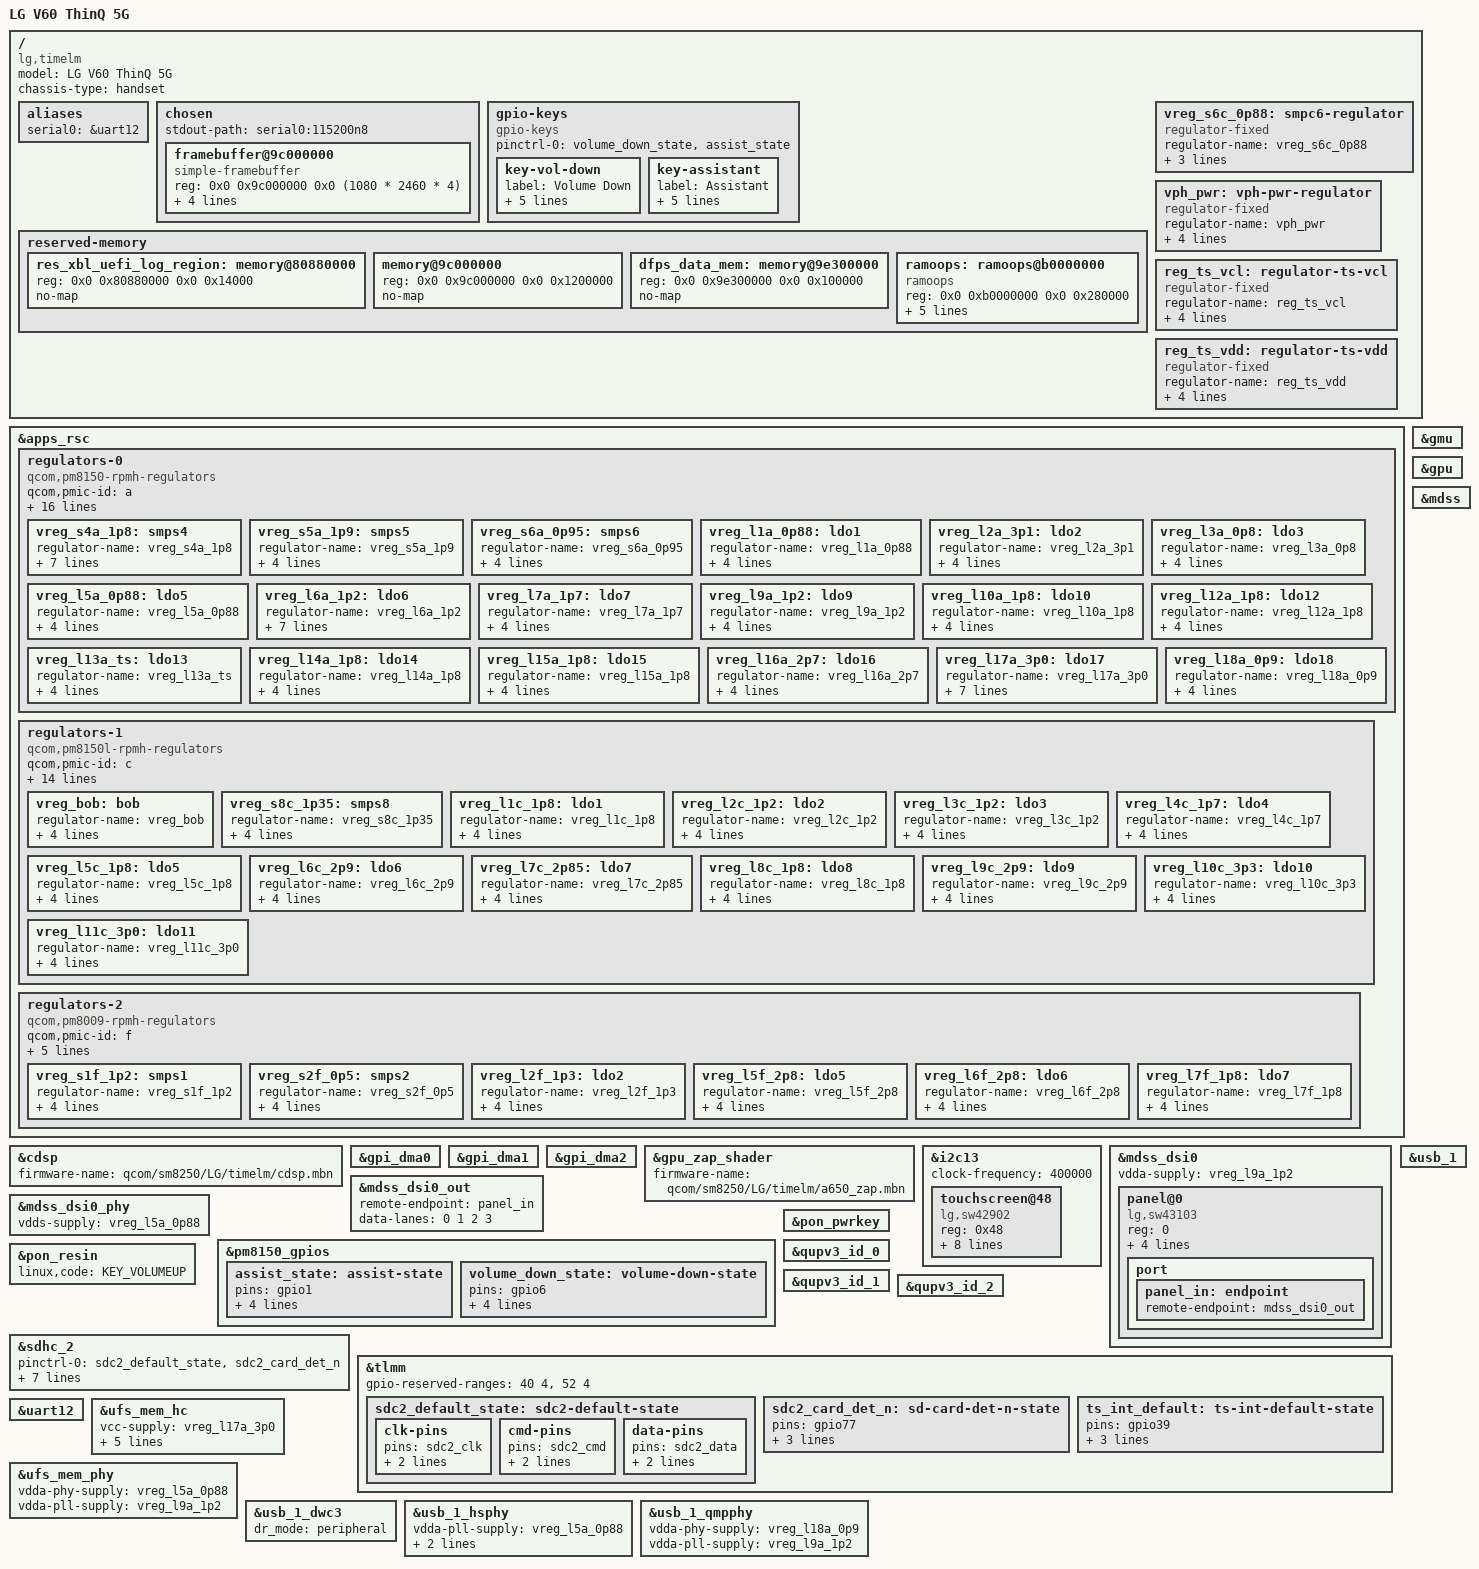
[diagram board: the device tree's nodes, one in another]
// SPDX-License-Identifier: BSD-3-Clause
/*
 * Copyright (c) 2026 Abdur Rofik <rofikcoga@gmail.com>
 * Device Tree for LG V60 ThinQ 5G (timelm / LM-V600)
 */

/dts-v1/;

#include <dt-bindings/gpio/gpio.h>
#include <dt-bindings/input/input.h>
#include <dt-bindings/regulator/qcom,rpmh-regulator.h>
#include "sm8250.dtsi"
#include "pm8150.dtsi"
#include "pm8150b.dtsi"
#include "pm8150l.dtsi"

/ {
	model = "LG V60 ThinQ 5G";
	compatible = "lg,timelm", "qcom,sm8250";
	chassis-type = "handset";

	aliases {
		serial0 = &uart12;
	};

	chosen {
		stdout-path = "serial0:115200n8";
		#address-cells = <2>;
		#size-cells = <2>;
		ranges;

		framebuffer@9c000000 {
			compatible = "simple-framebuffer";
			reg = <0x0 0x9c000000 0x0 (1080 * 2460 * 4)>;
			width = <1080>;
			height = <2460>;
			stride = <(1080 * 4)>;
			format = "a8r8g8b8";
		};
	};

	gpio-keys {
		compatible = "gpio-keys";

		pinctrl-names = "default";
		pinctrl-0 = <&volume_down_state>, <&assist_state>;

		key-vol-down {
			label = "Volume Down";
			gpios = <&pm8150_gpios 6 GPIO_ACTIVE_LOW>;
			linux,code = <KEY_VOLUMEDOWN>;
			debounce-interval = <15>;
			linux,can-disable;
			wakeup-source;
		};

		key-assistant {
			label = "Assistant";
			gpios = <&pm8150_gpios 1 GPIO_ACTIVE_LOW>;
			linux,code = <KEY_ASSISTANT>;
			debounce-interval = <15>;
			linux,can-disable;
			wakeup-source;
		};
	};

	reserved-memory {
		res_xbl_uefi_log_region: memory@80880000 {
			reg = <0x0 0x80880000 0x0 0x14000>;
			no-map;
		};

		memory@9c000000 {
			reg = <0x0 0x9c000000 0x0 0x1200000>;
			no-map;
		};

		dfps_data_mem: memory@9e300000 {
			reg = <0x0 0x9e300000 0x0 0x100000>;
			no-map;
		};

		ramoops: ramoops@b0000000 {
			compatible = "ramoops";
			reg = <0x0 0xb0000000 0x0 0x280000>;
			record-size = <0x40000>;
			console-size = <0x40000>;
			ftrace-size = <0x40000>;
			pmsg-size = <0x100000>;
			no-map;
		};
	};

	vreg_s6c_0p88: smpc6-regulator {
		compatible = "regulator-fixed";
		regulator-name = "vreg_s6c_0p88";
		regulator-min-microvolt = <880000>;
		regulator-max-microvolt = <880000>;
		regulator-always-on;
	};

	vph_pwr: vph-pwr-regulator {
		compatible = "regulator-fixed";
		regulator-name = "vph_pwr";
		regulator-min-microvolt = <3700000>;
		regulator-max-microvolt = <3700000>;
		regulator-always-on;
		regulator-boot-on;
	};

	reg_ts_vcl: regulator-ts-vcl {
		compatible = "regulator-fixed";
		regulator-name = "reg_ts_vcl";
		regulator-min-microvolt = <3300000>;
		regulator-max-microvolt = <3300000>;
		gpio = <&pm8150_gpios 8 GPIO_ACTIVE_HIGH>;
		enable-active-high;
	};

	reg_ts_vdd: regulator-ts-vdd {
		compatible = "regulator-fixed";
		regulator-name = "reg_ts_vdd";
		regulator-min-microvolt = <1800000>;
		regulator-max-microvolt = <1800000>;
		gpio = <&pm8150_gpios 9 GPIO_ACTIVE_HIGH>;
		enable-active-high;
	};
};

&apps_rsc {
	regulators-0 {
		compatible = "qcom,pm8150-rpmh-regulators";
		qcom,pmic-id = "a";

		vdd-s1-supply = <&vph_pwr>;
		vdd-s2-supply = <&vph_pwr>;
		vdd-s3-supply = <&vph_pwr>;
		vdd-s4-supply = <&vph_pwr>;
		vdd-s5-supply = <&vph_pwr>;
		vdd-s6-supply = <&vph_pwr>;
		vdd-s7-supply = <&vph_pwr>;
		vdd-s8-supply = <&vph_pwr>;
		vdd-s9-supply = <&vph_pwr>;
		vdd-s10-supply = <&vph_pwr>;
		vdd-l1-l8-l11-supply = <&vreg_s6c_0p88>;
		vdd-l2-l10-supply = <&vreg_bob>;
		vdd-l3-l4-l5-l18-supply = <&vreg_s6a_0p95>;
		vdd-l6-l9-supply = <&vreg_s8c_1p35>;
		vdd-l7-l12-l14-l15-supply = <&vreg_s5a_1p9>;
		vdd-l13-l16-l17-supply = <&vreg_bob>;

		vreg_s4a_1p8: smps4 {
			regulator-name = "vreg_s4a_1p8";
			regulator-min-microvolt = <1800000>;
			regulator-max-microvolt = <1800000>;
			regulator-initial-mode = <RPMH_REGULATOR_MODE_HPM>;
			regulator-allow-set-load;
			regulator-allowed-modes = <RPMH_REGULATOR_MODE_LPM
						   RPMH_REGULATOR_MODE_HPM>;
		};

		vreg_s5a_1p9: smps5 {
			regulator-name = "vreg_s5a_1p9";
			regulator-min-microvolt = <1900000>;
			regulator-max-microvolt = <2040000>;
			regulator-initial-mode = <RPMH_REGULATOR_MODE_HPM>;
		};

		vreg_s6a_0p95: smps6 {
			regulator-name = "vreg_s6a_0p95";
			regulator-min-microvolt = <950000>;
			regulator-max-microvolt = <1128000>;
			regulator-initial-mode = <RPMH_REGULATOR_MODE_HPM>;
		};

		vreg_l1a_0p88: ldo1 {
			regulator-name = "vreg_l1a_0p88";
			regulator-min-microvolt = <880000>;
			regulator-max-microvolt = <880000>;
			regulator-initial-mode = <RPMH_REGULATOR_MODE_HPM>;
		};

		vreg_l2a_3p1: ldo2 {
			regulator-name = "vreg_l2a_3p1";
			regulator-min-microvolt = <3072000>;
			regulator-max-microvolt = <3072000>;
			regulator-initial-mode = <RPMH_REGULATOR_MODE_HPM>;
		};

		vreg_l3a_0p8: ldo3 {
			regulator-name = "vreg_l3a_0p8";
			regulator-min-microvolt = <800000>;
			regulator-max-microvolt = <800000>;
			regulator-initial-mode = <RPMH_REGULATOR_MODE_HPM>;
		};

		vreg_l5a_0p88: ldo5 {
			regulator-name = "vreg_l5a_0p88";
			regulator-min-microvolt = <880000>;
			regulator-max-microvolt = <880000>;
			regulator-initial-mode = <RPMH_REGULATOR_MODE_HPM>;
		};

		vreg_l6a_1p2: ldo6 {
			regulator-name = "vreg_l6a_1p2";
			regulator-min-microvolt = <1200000>;
			regulator-max-microvolt = <1200000>;
			regulator-initial-mode = <RPMH_REGULATOR_MODE_HPM>;
			regulator-allow-set-load;
			regulator-allowed-modes = <RPMH_REGULATOR_MODE_LPM
						   RPMH_REGULATOR_MODE_HPM>;
		};

		vreg_l7a_1p7: ldo7 {
			regulator-name = "vreg_l7a_1p7";
			regulator-min-microvolt = <1704000>;
			regulator-max-microvolt = <1800000>;
			regulator-initial-mode = <RPMH_REGULATOR_MODE_HPM>;
		};

		vreg_l9a_1p2: ldo9 {
			regulator-name = "vreg_l9a_1p2";
			regulator-min-microvolt = <1200000>;
			regulator-max-microvolt = <1200000>;
			regulator-initial-mode = <RPMH_REGULATOR_MODE_HPM>;
		};

		vreg_l10a_1p8: ldo10 {
			regulator-name = "vreg_l10a_1p8";
			regulator-min-microvolt = <1800000>;
			regulator-max-microvolt = <1800000>;
			regulator-initial-mode = <RPMH_REGULATOR_MODE_HPM>;
		};

		vreg_l12a_1p8: ldo12 {
			regulator-name = "vreg_l12a_1p8";
			regulator-min-microvolt = <1800000>;
			regulator-max-microvolt = <1800000>;
			regulator-initial-mode = <RPMH_REGULATOR_MODE_HPM>;
		};

		vreg_l13a_ts: ldo13 {
			regulator-name = "vreg_l13a_ts";
			regulator-min-microvolt = <3000000>;
			regulator-max-microvolt = <3000000>;
			regulator-initial-mode = <RPMH_REGULATOR_MODE_HPM>;
		};

		vreg_l14a_1p8: ldo14 {
			regulator-name = "vreg_l14a_1p8";
			regulator-min-microvolt = <1800000>;
			regulator-max-microvolt = <1800000>;
			regulator-initial-mode = <RPMH_REGULATOR_MODE_HPM>;
		};

		vreg_l15a_1p8: ldo15 {
			regulator-name = "vreg_l15a_1p8";
			regulator-min-microvolt = <1800000>;
			regulator-max-microvolt = <1800000>;
			regulator-initial-mode = <RPMH_REGULATOR_MODE_HPM>;
		};

		vreg_l16a_2p7: ldo16 {
			regulator-name = "vreg_l16a_2p7";
			regulator-min-microvolt = <2704000>;
			regulator-max-microvolt = <2960000>;
			regulator-initial-mode = <RPMH_REGULATOR_MODE_HPM>;
		};

		vreg_l17a_3p0: ldo17 {
			regulator-name = "vreg_l17a_3p0";
			regulator-min-microvolt = <2950000>;
			regulator-max-microvolt = <3008000>;
			regulator-initial-mode = <RPMH_REGULATOR_MODE_HPM>;
			regulator-allow-set-load;
			regulator-allowed-modes = <RPMH_REGULATOR_MODE_LPM
						   RPMH_REGULATOR_MODE_HPM>;
		};

		vreg_l18a_0p9: ldo18 {
			regulator-name = "vreg_l18a_0p9";
			regulator-min-microvolt = <880000>;
			regulator-max-microvolt = <912000>;
			regulator-initial-mode = <RPMH_REGULATOR_MODE_HPM>;
		};
	};

	regulators-1 {
		compatible = "qcom,pm8150l-rpmh-regulators";
		qcom,pmic-id = "c";

		vdd-s1-supply = <&vph_pwr>;
		vdd-s2-supply = <&vph_pwr>;
		vdd-s3-supply = <&vph_pwr>;
		vdd-s4-supply = <&vph_pwr>;
		vdd-s5-supply = <&vph_pwr>;
		vdd-s6-supply = <&vph_pwr>;
		vdd-s7-supply = <&vph_pwr>;
		vdd-s8-supply = <&vph_pwr>;
		vdd-l1-l8-supply = <&vreg_s4a_1p8>;
		vdd-l2-l3-supply = <&vreg_s8c_1p35>;
		vdd-l4-l5-l6-supply = <&vreg_bob>;
		vdd-l7-l11-supply = <&vreg_bob>;
		vdd-l9-l10-supply = <&vreg_bob>;
		vdd-bob-supply = <&vph_pwr>;

		vreg_bob: bob {
			regulator-name = "vreg_bob";
			regulator-min-microvolt = <3008000>;
			regulator-max-microvolt = <4000000>;
			regulator-initial-mode = <RPMH_REGULATOR_MODE_AUTO>;
		};

		vreg_s8c_1p35: smps8 {
			regulator-name = "vreg_s8c_1p35";
			regulator-min-microvolt = <1350000>;
			regulator-max-microvolt = <1400000>;
			regulator-initial-mode = <RPMH_REGULATOR_MODE_HPM>;
		};

		vreg_l1c_1p8: ldo1 {
			regulator-name = "vreg_l1c_1p8";
			regulator-min-microvolt = <1800000>;
			regulator-max-microvolt = <1800000>;
			regulator-initial-mode = <RPMH_REGULATOR_MODE_HPM>;
		};

		vreg_l2c_1p2: ldo2 {
			regulator-name = "vreg_l2c_1p2";
			regulator-min-microvolt = <1200000>;
			regulator-max-microvolt = <1200000>;
			regulator-initial-mode = <RPMH_REGULATOR_MODE_HPM>;
		};

		vreg_l3c_1p2: ldo3 {
			regulator-name = "vreg_l3c_1p2";
			regulator-min-microvolt = <1200000>;
			regulator-max-microvolt = <1200000>;
			regulator-initial-mode = <RPMH_REGULATOR_MODE_HPM>;
		};

		vreg_l4c_1p7: ldo4 {
			regulator-name = "vreg_l4c_1p7";
			regulator-min-microvolt = <1704000>;
			regulator-max-microvolt = <3000000>;
			regulator-initial-mode = <RPMH_REGULATOR_MODE_HPM>;
		};

		vreg_l5c_1p8: ldo5 {
			regulator-name = "vreg_l5c_1p8";
			regulator-min-microvolt = <1800000>;
			regulator-max-microvolt = <1800000>;
			regulator-initial-mode = <RPMH_REGULATOR_MODE_HPM>;
		};

		vreg_l6c_2p9: ldo6 {
			regulator-name = "vreg_l6c_2p9";
			regulator-min-microvolt = <1800000>;
			regulator-max-microvolt = <2960000>;
			regulator-initial-mode = <RPMH_REGULATOR_MODE_HPM>;
		};

		vreg_l7c_2p85: ldo7 {
			regulator-name = "vreg_l7c_2p85";
			regulator-min-microvolt = <2856000>;
			regulator-max-microvolt = <3104000>;
			regulator-initial-mode = <RPMH_REGULATOR_MODE_HPM>;
		};

		vreg_l8c_1p8: ldo8 {
			regulator-name = "vreg_l8c_1p8";
			regulator-min-microvolt = <1800000>;
			regulator-max-microvolt = <1800000>;
			regulator-initial-mode = <RPMH_REGULATOR_MODE_HPM>;
		};

		vreg_l9c_2p9: ldo9 {
			regulator-name = "vreg_l9c_2p9";
			regulator-min-microvolt = <2704000>;
			regulator-max-microvolt = <2960000>;
			regulator-initial-mode = <RPMH_REGULATOR_MODE_HPM>;
		};

		vreg_l10c_3p3: ldo10 {
			regulator-name = "vreg_l10c_3p3";
			regulator-min-microvolt = <3000000>;
			regulator-max-microvolt = <3304000>;
			regulator-initial-mode = <RPMH_REGULATOR_MODE_HPM>;
		};

		vreg_l11c_3p0: ldo11 {
			regulator-name = "vreg_l11c_3p0";
			regulator-min-microvolt = <3000000>;
			regulator-max-microvolt = <3312000>;
			regulator-initial-mode = <RPMH_REGULATOR_MODE_HPM>;
		};
	};

	regulators-2 {
		compatible = "qcom,pm8009-rpmh-regulators";
		qcom,pmic-id = "f";

		vdd-s1-supply = <&vph_pwr>;
		vdd-s2-supply = <&vreg_bob>;
		vdd-l2-supply = <&vreg_s8c_1p35>;
		vdd-l5-l6-supply = <&vreg_bob>;
		vdd-l7-supply = <&vreg_s4a_1p8>;

		vreg_s1f_1p2: smps1 {
			regulator-name = "vreg_s1f_1p2";
			regulator-min-microvolt = <1200000>;
			regulator-max-microvolt = <1200000>;
			regulator-initial-mode = <RPMH_REGULATOR_MODE_HPM>;
		};

		vreg_s2f_0p5: smps2 {
			regulator-name = "vreg_s2f_0p5";
			regulator-min-microvolt = <512000>;
			regulator-max-microvolt = <1100000>;
			regulator-initial-mode = <RPMH_REGULATOR_MODE_HPM>;
		};

		vreg_l2f_1p3: ldo2 {
			regulator-name = "vreg_l2f_1p3";
			regulator-min-microvolt = <1304000>;
			regulator-max-microvolt = <1304000>;
			regulator-initial-mode = <RPMH_REGULATOR_MODE_HPM>;
		};

		vreg_l5f_2p8: ldo5 {
			regulator-name = "vreg_l5f_2p8";
			regulator-min-microvolt = <2800000>;
			regulator-max-microvolt = <2800000>;
			regulator-initial-mode = <RPMH_REGULATOR_MODE_HPM>;
		};

		vreg_l6f_2p8: ldo6 {
			regulator-name = "vreg_l6f_2p8";
			regulator-min-microvolt = <2800000>;
			regulator-max-microvolt = <2800000>;
			regulator-initial-mode = <RPMH_REGULATOR_MODE_HPM>;
		};

		vreg_l7f_1p8: ldo7 {
			regulator-name = "vreg_l7f_1p8";
			regulator-min-microvolt = <1800000>;
			regulator-max-microvolt = <1800000>;
			regulator-initial-mode = <RPMH_REGULATOR_MODE_HPM>;
		};
	};
};

&cdsp {
	firmware-name = "qcom/sm8250/LG/timelm/cdsp.mbn";
	status = "okay";
};

&gmu {
	status = "okay";
};

&gpi_dma0 {
	status = "okay";
};

&gpi_dma1 {
	status = "okay";
};

&gpi_dma2 {
	status = "okay";
};

&gpu {
	status = "okay";
};

&gpu_zap_shader {
	firmware-name = "qcom/sm8250/LG/timelm/a650_zap.mbn";
};

&i2c13 {
	status = "okay";
	clock-frequency = <400000>;

	touchscreen@48 {
		compatible = "lg,sw42902";
		reg = <0x48>;

		interrupts-extended = <&tlmm 39 IRQ_TYPE_LEVEL_LOW>;

		pinctrl-names = "default";
		pinctrl-0 = <&ts_int_default>;

		reset-gpios = <&tlmm 38 GPIO_ACTIVE_LOW>;
		vcl-supply = <&reg_ts_vcl>;
		vdd-supply = <&reg_ts_vdd>;

		touchscreen-size-x = <1080>;
		touchscreen-size-y = <2460>;
	};
};

&mdss {
	status = "okay";
};

&mdss_dsi0 {
	vdda-supply = <&vreg_l9a_1p2>;
	status = "okay";

	panel@0 {
		compatible = "lg,sw43103";
		reg = <0>;

		vddi-supply = <&vreg_l14a_1p8>;
		vpnl-supply = <&vreg_l11c_3p0>;

		reset-gpios = <&tlmm 75 GPIO_ACTIVE_LOW>;
		enable-gpios = <&pm8150l_gpios 4 GPIO_ACTIVE_HIGH>;

		port {
			panel_in: endpoint {
				remote-endpoint = <&mdss_dsi0_out>;
			};
		};
	};
};

&mdss_dsi0_out {
	remote-endpoint = <&panel_in>;
	data-lanes = <0 1 2 3>;
};

&mdss_dsi0_phy {
	vdds-supply = <&vreg_l5a_0p88>;
	status = "okay";
};

&pm8150_gpios {
	assist_state: assist-state {
		pins = "gpio1";
		function = "normal";
		input-enable;
		bias-pull-up;
		power-source = <0>;
	};

	volume_down_state: volume-down-state {
		pins = "gpio6";
		function = "normal";
		input-enable;
		bias-pull-up;
		power-source = <0>;
	};
};

&pon_pwrkey {
	status = "okay";
};

&pon_resin {
	status = "okay";
	linux,code = <KEY_VOLUMEUP>;
};

&qupv3_id_0 {
	status = "okay";
};

&qupv3_id_1 {
	status = "okay";
};

&qupv3_id_2 {
	status = "okay";
};

&sdhc_2 {
	status = "okay";

	pinctrl-names = "default", "sleep";
	pinctrl-0 = <&sdc2_default_state>, <&sdc2_card_det_n>;
	pinctrl-1 = <&sdc2_sleep_state>, <&sdc2_card_det_n>;

	cd-gpios = <&tlmm 77 GPIO_ACTIVE_LOW>;
	vmmc-supply = <&vreg_l9c_2p9>;
	vqmmc-supply = <&vreg_l6c_2p9>;
	bus-width = <4>;
	no-sdio;
	no-mmc;
};

&tlmm {
	gpio-reserved-ranges = <40 4>, <52 4>;

	sdc2_default_state: sdc2-default-state {
		clk-pins {
			pins = "sdc2_clk";
			drive-strength = <16>;
			bias-disable;
		};

		cmd-pins {
			pins = "sdc2_cmd";
			drive-strength = <16>;
			bias-pull-up;
		};

		data-pins {
			pins = "sdc2_data";
			drive-strength = <16>;
			bias-pull-up;
		};
	};

	sdc2_card_det_n: sd-card-det-n-state {
		pins = "gpio77";
		function = "gpio";
		drive-strength = <2>;
		bias-pull-up;
	};

	ts_int_default: ts-int-default-state {
		pins = "gpio39";
		function = "gpio";
		drive-strength = <8>;
		bias-pull-up;
	};
};

&uart12 {
	status = "okay";
};

&ufs_mem_hc {
	status = "okay";

	vcc-supply = <&vreg_l17a_3p0>;
	vcc-max-microamp = <800000>;
	vccq-supply = <&vreg_l6a_1p2>;
	vccq-max-microamp = <800000>;
	vccq2-supply = <&vreg_s4a_1p8>;
	vccq2-max-microamp = <800000>;
};

&ufs_mem_phy {
	status = "okay";

	vdda-phy-supply = <&vreg_l5a_0p88>;
	vdda-pll-supply = <&vreg_l9a_1p2>;
};

&usb_1 {
	status = "okay";
};

&usb_1_dwc3 {
	dr_mode = "peripheral";
};

&usb_1_hsphy {
	status = "okay";

	vdda-pll-supply = <&vreg_l5a_0p88>;
	vdda18-supply = <&vreg_l12a_1p8>;
	vdda33-supply = <&vreg_l2a_3p1>;
};

&usb_1_qmpphy {
	status = "okay";

	vdda-phy-supply = <&vreg_l18a_0p9>;
	vdda-pll-supply = <&vreg_l9a_1p2>;
};
